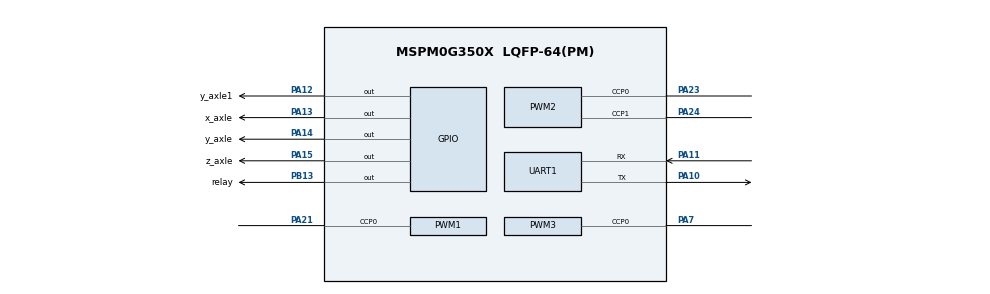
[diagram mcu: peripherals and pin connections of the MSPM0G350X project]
/**
 * @cliArgs --device "MSPM0G350X" --package "LQFP-64(PM)" --part "Default" --product "mspm0_sdk@2.01.00.03"
 * @versions {"tool":"1.20.0+3587"}
 */

/**
 * Import the modules used in this configuration.
 */
const GPIO   = scripting.addModule("/ti/driverlib/GPIO", {}, false);
const GPIO1  = GPIO.addInstance();
const GPIO2  = GPIO.addInstance();
const GPIO3  = GPIO.addInstance();
const GPIO4  = GPIO.addInstance();
const GPIO5  = GPIO.addInstance();
const PWM    = scripting.addModule("/ti/driverlib/PWM", {}, false);
const PWM1   = PWM.addInstance();
const PWM2   = PWM.addInstance();
const PWM3   = PWM.addInstance();
const SYSCTL = scripting.addModule("/ti/driverlib/SYSCTL");
const TIMER  = scripting.addModule("/ti/driverlib/TIMER", {}, false);
const TIMER1 = TIMER.addInstance();
const UART   = scripting.addModule("/ti/driverlib/UART", {}, false);
const UART1  = UART.addInstance();

/**
 * Write custom configuration values to the imported modules.
 */
const divider4       = system.clockTree["PLL_CLK0_DIV"];
divider4.divideValue = 4;

const divider6       = system.clockTree["PLL_CLK2X_DIV"];
divider6.divideValue = 4;

const divider7       = system.clockTree["PLL_PDIV"];
divider7.divideValue = 4;

const divider9       = system.clockTree["UDIV"];
divider9.divideValue = 2;

const gate7  = system.clockTree["MFCLKGATE"];
gate7.enable = true;

const multiplier2         = system.clockTree["PLL_QDIV"];
multiplier2.multiplyValue = 20;

const mux3       = system.clockTree["EXCLKMUX"];
mux3.inputSelect = "EXCLKMUX_PLLCLK1_OUT";

const mux4       = system.clockTree["EXHFMUX"];
mux4.inputSelect = "EXHFMUX_XTAL";

const mux8       = system.clockTree["HSCLKMUX"];
mux8.inputSelect = "HSCLKMUX_SYSPLL2X";

const mux10       = system.clockTree["MFPCLKMUX"];
mux10.inputSelect = "MFPCLKMUX_HFCLK";

const pinFunction4       = system.clockTree["HFXT"];
pinFunction4.inputFreq   = 40;
pinFunction4.enable      = true;
pinFunction4.HFXTStartup = 20;

GPIO1.$name                         = "LED";
GPIO1.port                          = "PORTA";
GPIO1.associatedPins[0].$name       = "LED_0";
GPIO1.associatedPins[0].assignedPin = "0";

const Board = scripting.addModule("/ti/driverlib/Board", {}, false);

GPIO2.$name                          = "I2C";
GPIO2.associatedPins.create(2);
GPIO2.associatedPins[0].assignedPort = "PORTB";
GPIO2.associatedPins[0].$name        = "SDA";
GPIO2.associatedPins[0].assignedPin  = "15";
GPIO2.associatedPins[0].initialValue = "SET";
GPIO2.associatedPins[1].$name        = "SCL";
GPIO2.associatedPins[1].assignedPort = "PORTA";
GPIO2.associatedPins[1].assignedPin  = "17";
GPIO2.associatedPins[1].initialValue = "SET";

GPIO3.$name                              = "KEY";
GPIO3.port                               = "PORTB";
GPIO3.associatedPins.create(3);
GPIO3.associatedPins[0].$name            = "KEY_1";
GPIO3.associatedPins[0].direction        = "INPUT";
GPIO3.associatedPins[0].assignedPin      = "21";
GPIO3.associatedPins[0].internalResistor = "PULL_UP";
GPIO3.associatedPins[1].$name            = "KEY_2";
GPIO3.associatedPins[1].direction        = "INPUT";
GPIO3.associatedPins[1].internalResistor = "PULL_UP";
GPIO3.associatedPins[1].assignedPin      = "23";
GPIO3.associatedPins[2].$name            = "KEY_3";
GPIO3.associatedPins[2].direction        = "INPUT";
GPIO3.associatedPins[2].internalResistor = "PULL_UP";
GPIO3.associatedPins[2].assignedPin      = "24";

GPIO4.$name                         = "DIR";
GPIO4.port                          = "PORTA";
GPIO4.associatedPins.create(4);
GPIO4.associatedPins[0].ioStructure = "HS";
GPIO4.associatedPins[0].$name       = "x_axle";
GPIO4.associatedPins[0].pin.$assign = "PA13";
GPIO4.associatedPins[1].ioStructure = "HS";
GPIO4.associatedPins[1].$name       = "y_axle";
GPIO4.associatedPins[1].pin.$assign = "PA14";
GPIO4.associatedPins[2].ioStructure = "HS";
GPIO4.associatedPins[2].$name       = "y_axle1";
GPIO4.associatedPins[2].pin.$assign = "PA12";
GPIO4.associatedPins[3].$name       = "z_axle";
GPIO4.associatedPins[3].pin.$assign = "PA15";

GPIO5.$name                         = "Relay";
GPIO5.associatedPins[0].$name       = "relay";
GPIO5.associatedPins[0].pin.$assign = "PB13";

PWM1.$name                      = "PWM_0";
PWM1.pwmMode                    = "EDGE_ALIGN_UP";
PWM1.clockSource                = "MFCLK";
PWM1.clockDivider               = 4;
PWM1.ccIndex                    = [0];
PWM1.peripheral.$assign         = "TIMG6";
PWM1.peripheral.ccp0Pin.$assign = "PA21";
PWM1.PWM_CHANNEL_0.$name        = "ti_driverlib_pwm_PWMTimerCC0";
PWM1.PWM_CHANNEL_0.initVal      = "HIGH";
PWM1.PWM_CHANNEL_0.dutyCycle    = 50;
PWM1.ccp0PinConfig.$name        = "ti_driverlib_gpio_GPIOPinGeneric0";

PWM2.$name                      = "PWM_1";
PWM2.clockSource                = "MFCLK";
PWM2.clockDivider               = 4;
PWM2.pwmMode                    = "EDGE_ALIGN_UP";
PWM2.peripheral.$assign         = "TIMG7";
PWM2.peripheral.ccp0Pin.$assign = "PA23";
PWM2.peripheral.ccp1Pin.$assign = "PA24";
PWM2.PWM_CHANNEL_0.$name        = "ti_driverlib_pwm_PWMTimerCC1";
PWM2.PWM_CHANNEL_0.initVal      = "HIGH";
PWM2.PWM_CHANNEL_0.dutyCycle    = 50;
PWM2.PWM_CHANNEL_1.$name        = "ti_driverlib_pwm_PWMTimerCC2";
PWM2.ccp0PinConfig.$name        = "ti_driverlib_gpio_GPIOPinGeneric1";
PWM2.ccp1PinConfig.$name        = "ti_driverlib_gpio_GPIOPinGeneric4";

PWM3.$name                      = "PWM_2";
PWM3.clockSource                = "MFCLK";
PWM3.clockDivider               = 4;
PWM3.pwmMode                    = "EDGE_ALIGN_UP";
PWM3.ccIndex                    = [0];
PWM3.peripheral.$assign         = "TIMG8";
PWM3.peripheral.ccp0Pin.$assign = "PA7";
PWM3.PWM_CHANNEL_0.$name        = "ti_driverlib_pwm_PWMTimerCC3";
PWM3.PWM_CHANNEL_0.initVal      = "HIGH";
PWM3.PWM_CHANNEL_0.dutyCycle    = 50;
PWM3.ccp0PinConfig.$name        = "ti_driverlib_gpio_GPIOPinGeneric5";

SYSCTL.forceDefaultClkConfig = true;
SYSCTL.clockTreeEn           = true;

TIMER1.timerMode            = "PERIODIC_UP";
TIMER1.timerStartTimer     = true;
TIMER1.retentionRestoreCnt = true;
TIMER1.interruptPriority   = "3";
TIMER1.timerClkDiv         = 8;
TIMER1.$name               = "TIMG_0";
TIMER1.timerClkPrescale    = 5;
TIMER1.interrupts          = ["LOAD"];
TIMER1.timerPeriod         = "10ms";
TIMER1.peripheral.$assign  = "TIMG0";

UART1.$name                    = "UART_0";
UART1.targetBaudRate           = 115200;
UART1.enableFIFO               = true;
UART1.enabledInterrupts        = ["RX","TX"];
UART1.interruptPriority        = "0";
UART1.peripheral.$assign       = "UART0";
UART1.peripheral.rxPin.$assign = "PA11";
UART1.peripheral.txPin.$assign = "PA10";
UART1.txPinConfig.$name        = "ti_driverlib_gpio_GPIOPinGeneric2";
UART1.rxPinConfig.$name        = "ti_driverlib_gpio_GPIOPinGeneric3";

/**
 * Pinmux solution for unlocked pins/peripherals. This ensures that minor changes to the automatic solver in a future
 * version of the tool will not impact the pinmux you originally saw.  These lines can be completely deleted in order to
 * re-solve from scratch.
 */
pinFunction4.peripheral.$suggestSolution           = "SYSCTL";
pinFunction4.peripheral.hfxInPin.$suggestSolution  = "PA5";
pinFunction4.peripheral.hfxOutPin.$suggestSolution = "PA6";
GPIO1.associatedPins[0].pin.$suggestSolution       = "PA0";
Board.peripheral.$suggestSolution                  = "DEBUGSS";
Board.peripheral.swclkPin.$suggestSolution         = "PA20";
Board.peripheral.swdioPin.$suggestSolution         = "PA19";
GPIO2.associatedPins[0].pin.$suggestSolution       = "PB15";
GPIO2.associatedPins[1].pin.$suggestSolution       = "PA17";
GPIO3.associatedPins[0].pin.$suggestSolution       = "PB21";
GPIO3.associatedPins[1].pin.$suggestSolution       = "PB23";
GPIO3.associatedPins[2].pin.$suggestSolution       = "PB24";
